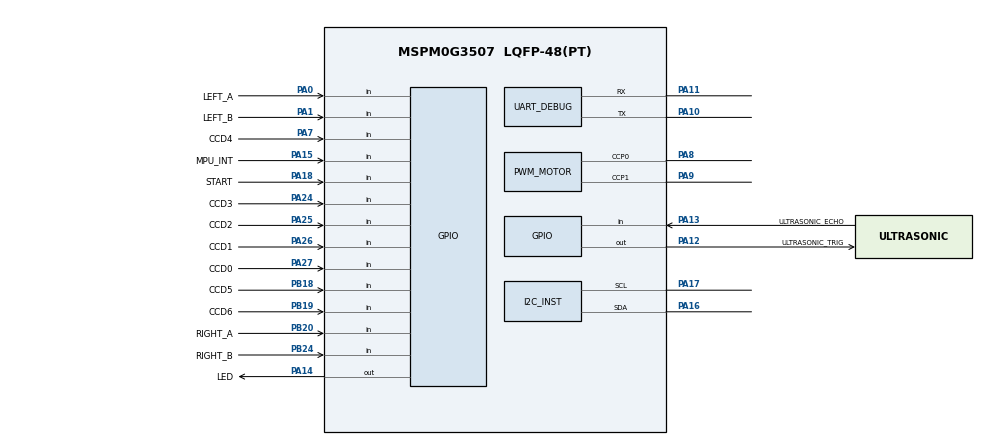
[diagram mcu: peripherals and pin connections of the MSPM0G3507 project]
/**
 * nuedc_car — 完整 SysConfig 配置
 * 芯片：MSPM0G3507（地猛星开发板）
 *
 * 引脚分配：
 *   PA8  = TIMA0_CCP0 (左电机 PWM)
 *   PA9  = TIMA0_CCP1 (右电机 PWM)
 *   PB2  = AIN1, PB3 = AIN2 (左电机方向)
 *   PB8  = BIN1, PB9 = BIN2 (右电机方向)
 *   PB6  = STBY (TB6612 使能)
 *   PB7  = 蜂鸣器
 *   PA16 = I2C1_SDA, PA17 = I2C1_SCL (MPU6050 + OLED)
 *   PA15 = MPU6050 INT
 *   PA27/PA26/PA25/PA24/PA7/PB18/PB19 = 7 路数字灰度
 *   PA10/PA11 = UART0 (调试串口)
 *   PA14 = LED, PA18 = 按键
 *   PA12 = 超声波 TRIG 预留, PA13 = 超声波 ECHO 预留
 *   PA0/PA1 = 左编码器 A/B, PB20/PB24 = 右编码器 A/B
 */

//@cliArgs --device "MSPM0G350X" --package "LQFP-48(PT)" --part "Default"
//@v2CliArgs --device "MSPM0G3507" --package "LQFP-48(PT)"

const Board         = scripting.addModule("/ti/driverlib/Board", {}, false);
const SYSCTL        = scripting.addModule("/ti/driverlib/SYSCTL");
const ProjectConfig = scripting.addModule("/ti/project_config/ProjectConfig");
const GPIO          = scripting.addModule("/ti/driverlib/GPIO", {}, false);
const UART          = scripting.addModule("/ti/driverlib/UART", {}, false);
const PWM           = scripting.addModule("/ti/driverlib/PWM", {}, false);
const I2C           = scripting.addModule("/ti/driverlib/I2C", {}, false);

const GPIO_NOTIFY    = GPIO.addInstance();
const GPIO_CONTROL   = GPIO.addInstance();
const GPIO_MOTOR_DIR = GPIO.addInstance();
const GPIO_BUZZER    = GPIO.addInstance();
const GPIO_IMU       = GPIO.addInstance();
const GPIO_RESERVED  = GPIO.addInstance();
const GPIO_LINE_A    = GPIO.addInstance();
const GPIO_LINE_B    = GPIO.addInstance();
const GPIO_ENCODER_A = GPIO.addInstance();
const GPIO_ENCODER_B = GPIO.addInstance();
const UART_DEBUG     = UART.addInstance();
const PWM_MOTOR      = PWM.addInstance();
const I2C_INST       = I2C.addInstance();

ProjectConfig.deviceSpin = "MSPM0G3507";

/* ========== 时钟 ========== */
SYSCTL.forceDefaultClkConfig = true;
SYSCTL.clockTreeEn = true;
SYSCTL.validateClkStatus = true;

/* ========== 板载 LED (PA14) ========== */
GPIO_NOTIFY.$name = "GPIO_NOTIFY";
GPIO_NOTIFY.port = "PORTA";
GPIO_NOTIFY.portSegment = "Lower";
GPIO_NOTIFY.associatedPins[0].$name = "LED";
GPIO_NOTIFY.associatedPins[0].assignedPort = "PORTA";
GPIO_NOTIFY.associatedPins[0].assignedPortSegment = "Lower";
GPIO_NOTIFY.associatedPins[0].assignedPin = "14";
GPIO_NOTIFY.associatedPins[0].pin.$assign = "PA14";
GPIO_NOTIFY.associatedPins[0].initialValue = "CLEARED";

/* ========== 板载按键 (PA18) ========== */
GPIO_CONTROL.$name = "GPIO_CONTROL";
GPIO_CONTROL.port = "PORTA";
GPIO_CONTROL.portSegment = "Upper";
GPIO_CONTROL.associatedPins[0].$name = "START";
GPIO_CONTROL.associatedPins[0].direction = "INPUT";
GPIO_CONTROL.associatedPins[0].assignedPort = "PORTA";
GPIO_CONTROL.associatedPins[0].assignedPortSegment = "Upper";
GPIO_CONTROL.associatedPins[0].assignedPin = "18";
GPIO_CONTROL.associatedPins[0].pin.$assign = "PA18";

/* ========== 调试串口 UART0 (PA10/PA11) ========== */
UART_DEBUG.$name = "UART_DEBUG";
UART_DEBUG.targetBaudRate = 115200;
UART_DEBUG.enableFIFO = true;
UART_DEBUG.rxFifoThreshold = "DL_UART_RX_FIFO_LEVEL_ONE_ENTRY";
UART_DEBUG.txFifoThreshold = "DL_UART_TX_FIFO_LEVEL_ONE_ENTRY";
UART_DEBUG.enabledInterrupts = ["RX"];
UART_DEBUG.peripheral.$assign = "UART0";
UART_DEBUG.peripheral.txPin.$assign = "PA10";
UART_DEBUG.peripheral.rxPin.$assign = "PA11";

/* ========== 电机 PWM — TIMA0, PA8(C0)/PA9(C1) ========== */
PWM_MOTOR.$name = "PWM_MOTOR";
PWM_MOTOR.peripheral.$assign = "TIMA0";
PWM_MOTOR.peripheral.ccp0Pin.$assign = "PA8";
PWM_MOTOR.peripheral.ccp1Pin.$assign = "PA9";
PWM_MOTOR.timerCount = 1000;
PWM_MOTOR.ccIndex = [0, 1];
PWM_MOTOR.timerStartTimer = true;
PWM_MOTOR.PWM_CHANNEL_0.$name = "ti_driverlib_pwm_PWMTimerCC0";
PWM_MOTOR.PWM_CHANNEL_0.dutyCycle = 0;
PWM_MOTOR.PWM_CHANNEL_1.$name = "ti_driverlib_pwm_PWMTimerCC1";
PWM_MOTOR.PWM_CHANNEL_1.dutyCycle = 0;

/* ========== 电机方向 GPIO — PB2/PB3/PB8/PB9, PB6(STBY) ========== */
GPIO_MOTOR_DIR.$name = "GPIO_MOTOR_DIR";
GPIO_MOTOR_DIR.port = "PORTB";
GPIO_MOTOR_DIR.associatedPins.create(5);
GPIO_MOTOR_DIR.associatedPins[0].$name = "LEFT_AIN1";
GPIO_MOTOR_DIR.associatedPins[0].assignedPort = "PORTB";
GPIO_MOTOR_DIR.associatedPins[0].assignedPin = "2";
GPIO_MOTOR_DIR.associatedPins[0].initialValue = "CLEARED";
GPIO_MOTOR_DIR.associatedPins[1].$name = "LEFT_AIN2";
GPIO_MOTOR_DIR.associatedPins[1].assignedPort = "PORTB";
GPIO_MOTOR_DIR.associatedPins[1].assignedPin = "3";
GPIO_MOTOR_DIR.associatedPins[1].initialValue = "CLEARED";
GPIO_MOTOR_DIR.associatedPins[2].$name = "RIGHT_BIN1";
GPIO_MOTOR_DIR.associatedPins[2].assignedPort = "PORTB";
GPIO_MOTOR_DIR.associatedPins[2].assignedPin = "8";
GPIO_MOTOR_DIR.associatedPins[2].initialValue = "CLEARED";
GPIO_MOTOR_DIR.associatedPins[3].$name = "RIGHT_BIN2";
GPIO_MOTOR_DIR.associatedPins[3].assignedPort = "PORTB";
GPIO_MOTOR_DIR.associatedPins[3].assignedPin = "9";
GPIO_MOTOR_DIR.associatedPins[3].initialValue = "CLEARED";
GPIO_MOTOR_DIR.associatedPins[4].$name = "STBY";
GPIO_MOTOR_DIR.associatedPins[4].assignedPort = "PORTB";
GPIO_MOTOR_DIR.associatedPins[4].assignedPin = "6";
GPIO_MOTOR_DIR.associatedPins[4].initialValue = "SET";

/* ========== 蜂鸣器 (PB7) ========== */
GPIO_BUZZER.$name = "GPIO_BUZZER";
GPIO_BUZZER.port = "PORTB";
GPIO_BUZZER.associatedPins[0].$name = "BUZZ";
GPIO_BUZZER.associatedPins[0].assignedPort = "PORTB";
GPIO_BUZZER.associatedPins[0].assignedPin = "7";
GPIO_BUZZER.associatedPins[0].initialValue = "CLEARED";

/* ========== MPU6050 INT (PA15) ========== */
GPIO_IMU.$name = "GPIO_IMU";
GPIO_IMU.port = "PORTA";
GPIO_IMU.portSegment = "Lower";
GPIO_IMU.associatedPins[0].$name = "MPU_INT";
GPIO_IMU.associatedPins[0].direction = "INPUT";
GPIO_IMU.associatedPins[0].assignedPort = "PORTA";
GPIO_IMU.associatedPins[0].assignedPortSegment = "Lower";
GPIO_IMU.associatedPins[0].assignedPin = "15";
GPIO_IMU.associatedPins[0].pin.$assign = "PA15";

/* ========== 超声波预留 (PA12 TRIG / PA13 ECHO) ========== */
GPIO_RESERVED.$name = "GPIO_RESERVED";
GPIO_RESERVED.port = "PORTA";
GPIO_RESERVED.portSegment = "Lower";
GPIO_RESERVED.associatedPins.create(2);
GPIO_RESERVED.associatedPins[0].$name = "ULTRASONIC_TRIG";
GPIO_RESERVED.associatedPins[0].assignedPort = "PORTA";
GPIO_RESERVED.associatedPins[0].assignedPortSegment = "Lower";
GPIO_RESERVED.associatedPins[0].assignedPin = "12";
GPIO_RESERVED.associatedPins[0].pin.$assign = "PA12";
GPIO_RESERVED.associatedPins[0].initialValue = "CLEARED";
GPIO_RESERVED.associatedPins[1].$name = "ULTRASONIC_ECHO";
GPIO_RESERVED.associatedPins[1].direction = "INPUT";
GPIO_RESERVED.associatedPins[1].assignedPort = "PORTA";
GPIO_RESERVED.associatedPins[1].assignedPortSegment = "Lower";
GPIO_RESERVED.associatedPins[1].assignedPin = "13";
GPIO_RESERVED.associatedPins[1].pin.$assign = "PA13";

/* ========== I2C1 — MPU6050 + OLED (PA16/PA17) ========== */
I2C_INST.$name = "I2C_INST";
I2C_INST.basicEnableController = true;
I2C_INST.basicControllerBusSpeed = 400000;
I2C_INST.peripheral.$assign = "I2C1";
I2C_INST.peripheral.sdaPin.$assign = "PA16";
I2C_INST.peripheral.sclPin.$assign = "PA17";

/* ========== 7 路数字灰度 (PA27/PA26/PA25/PA24/PA7/PB18/PB19) ========== */
GPIO_LINE_A.$name = "GPIO_LINE_A";
GPIO_LINE_A.port = "PORTA";
GPIO_LINE_A.associatedPins.create(5);
GPIO_LINE_A.associatedPins[0].$name = "CCD0";
GPIO_LINE_A.associatedPins[0].direction = "INPUT";
GPIO_LINE_A.associatedPins[0].assignedPort = "PORTA";
GPIO_LINE_A.associatedPins[0].assignedPin = "27";
GPIO_LINE_A.associatedPins[0].pin.$assign = "PA27";
GPIO_LINE_A.associatedPins[1].$name = "CCD1";
GPIO_LINE_A.associatedPins[1].direction = "INPUT";
GPIO_LINE_A.associatedPins[1].assignedPort = "PORTA";
GPIO_LINE_A.associatedPins[1].assignedPin = "26";
GPIO_LINE_A.associatedPins[1].pin.$assign = "PA26";
GPIO_LINE_A.associatedPins[2].$name = "CCD2";
GPIO_LINE_A.associatedPins[2].direction = "INPUT";
GPIO_LINE_A.associatedPins[2].assignedPort = "PORTA";
GPIO_LINE_A.associatedPins[2].assignedPin = "25";
GPIO_LINE_A.associatedPins[2].pin.$assign = "PA25";
GPIO_LINE_A.associatedPins[3].$name = "CCD3";
GPIO_LINE_A.associatedPins[3].direction = "INPUT";
GPIO_LINE_A.associatedPins[3].assignedPort = "PORTA";
GPIO_LINE_A.associatedPins[3].assignedPin = "24";
GPIO_LINE_A.associatedPins[3].pin.$assign = "PA24";
GPIO_LINE_A.associatedPins[4].$name = "CCD4";
GPIO_LINE_A.associatedPins[4].direction = "INPUT";
GPIO_LINE_A.associatedPins[4].assignedPort = "PORTA";
GPIO_LINE_A.associatedPins[4].assignedPin = "7";
GPIO_LINE_A.associatedPins[4].pin.$assign = "PA7";

GPIO_LINE_B.$name = "GPIO_LINE_B";
GPIO_LINE_B.port = "PORTB";
GPIO_LINE_B.associatedPins.create(2);
GPIO_LINE_B.associatedPins[0].$name = "CCD5";
GPIO_LINE_B.associatedPins[0].direction = "INPUT";
GPIO_LINE_B.associatedPins[0].assignedPort = "PORTB";
GPIO_LINE_B.associatedPins[0].assignedPin = "18";
GPIO_LINE_B.associatedPins[0].pin.$assign = "PB18";
GPIO_LINE_B.associatedPins[1].$name = "CCD6";
GPIO_LINE_B.associatedPins[1].direction = "INPUT";
GPIO_LINE_B.associatedPins[1].assignedPort = "PORTB";
GPIO_LINE_B.associatedPins[1].assignedPin = "19";
GPIO_LINE_B.associatedPins[1].pin.$assign = "PB19";

/* ========== 编码器 GPIO 输入 (PA0/PA1, PB20/PB24) ========== */
GPIO_ENCODER_A.$name = "GPIO_ENCODER_A";
GPIO_ENCODER_A.port = "PORTA";
GPIO_ENCODER_A.associatedPins.create(2);
GPIO_ENCODER_A.associatedPins[0].$name = "LEFT_A";
GPIO_ENCODER_A.associatedPins[0].direction = "INPUT";
GPIO_ENCODER_A.associatedPins[0].assignedPort = "PORTA";
GPIO_ENCODER_A.associatedPins[0].assignedPin = "0";
GPIO_ENCODER_A.associatedPins[0].pin.$assign = "PA0";
GPIO_ENCODER_A.associatedPins[1].$name = "LEFT_B";
GPIO_ENCODER_A.associatedPins[1].direction = "INPUT";
GPIO_ENCODER_A.associatedPins[1].assignedPort = "PORTA";
GPIO_ENCODER_A.associatedPins[1].assignedPin = "1";
GPIO_ENCODER_A.associatedPins[1].pin.$assign = "PA1";

GPIO_ENCODER_B.$name = "GPIO_ENCODER_B";
GPIO_ENCODER_B.port = "PORTB";
GPIO_ENCODER_B.associatedPins.create(2);
GPIO_ENCODER_B.associatedPins[0].$name = "RIGHT_A";
GPIO_ENCODER_B.associatedPins[0].direction = "INPUT";
GPIO_ENCODER_B.associatedPins[0].assignedPort = "PORTB";
GPIO_ENCODER_B.associatedPins[0].assignedPin = "20";
GPIO_ENCODER_B.associatedPins[0].pin.$assign = "PB20";
GPIO_ENCODER_B.associatedPins[1].$name = "RIGHT_B";
GPIO_ENCODER_B.associatedPins[1].direction = "INPUT";
GPIO_ENCODER_B.associatedPins[1].assignedPort = "PORTB";
GPIO_ENCODER_B.associatedPins[1].assignedPin = "24";
GPIO_ENCODER_B.associatedPins[1].pin.$assign = "PB24";

/*
 * PA0/PA1 是 5V 容限开漏 IO，用作编码器时必须保持输入模式。
 * 灰度模块为数字输出型；若后续改用模拟灰度，CCD4 不能继续用 PA7。
 * 超声波接口预留：PA12(TRIG), PA13(ECHO)。ECHO 若来自 5V 模块，
 * 必须先分压/电平转换到 3.3V。
 */
